# target register map
Vendor: Vango; Series: TARGET; File version: 1.0
CPU: CM0 r0p0, little endian, no MPU, no FPU, 2 interrupt priority bits
Registers are 32-bit, read-write, reset 0x0 unless marked. A register's access mark holds for its fields unless they carry their own. Offsets are from the block's base; [hi:lo] are bit positions; {n}, {i} and the like mark numbered series; 'fields as' and 'values as' point back to an identical list.

## ANA — The Analog controller is used to control the analog function of TARGET.
Base 0x40014200
0x00 REG0 (reset mask 0xFF) — Analog register 0.
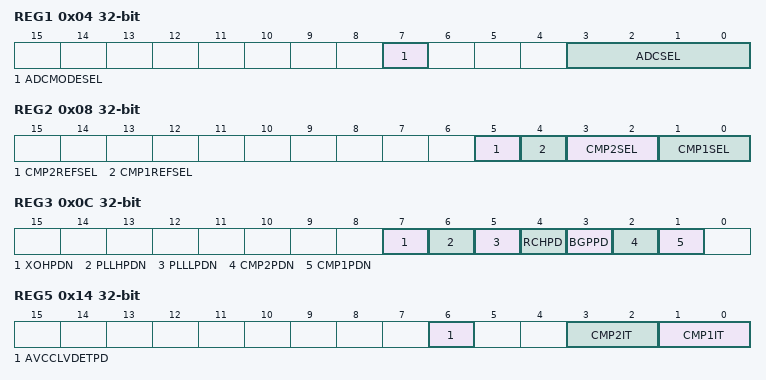
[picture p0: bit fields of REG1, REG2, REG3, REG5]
0x04 REG1 — Analog register 1.
  [7] ADCMODESEL — ADC mode select.
  [3:0] ADCSEL read-olny — ADC channel select.
0x08 REG2 — Analog register 2.
  [5] CMP2REFSEL — REF selection of CMP2.
  [4] CMP1REFSEL — REF selection of CMP1.
  [3:2] CMP2SEL — Signal source selection of comparator 2.
    0=CMP2_P_to_REF; 1=CMP2_N_to_REF; 0b1x=CMP2_P_to_N
  [1:0] CMP1SEL — Signal source selection of comparator 1.
    0=CMP1_P_to_REF; 1=CMP1_N_to_REF; 0b1x=CMP1_P_to_N
0x0C REG3 — Analog register 3.
  [7] XOHPDN — Turn on signal of 6.5536M crystal
  [6] PLLHPDN — PLLH (6.5536MHz input PLL) power up control signal.
  [5] PLLLPDN — PLLL (32768Hz input PLL) power up control signal.
  [4] RCHPD — RCH (6.5536M RC) power down control signal.
  [3] BGPPD — BGP power down control signal.
  [2] CMP2PDN — CMP2 power up control signal.
  [1] CMP1PDN — CMP1 power up control signal.
0x10 REG4 (reset mask 0xFF) — Analog register 4.
0x14 REG5 — Analog register 5.
  [6] AVCCLVDETPD — Power down low voltage detector.
  [3:2] CMP2IT — Bias current selection of CMP2
    0=20nA; 1=100nA; 0b1x=500nA
  [1:0] CMP1IT — Bias current selection of CMP1.
    0=20nA; 1=100nA; 0b1x=500nA
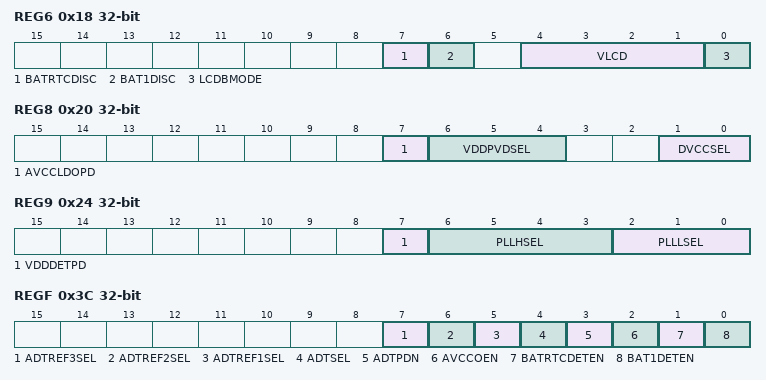
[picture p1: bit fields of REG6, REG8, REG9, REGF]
0x18 REG6 — Analog register 6.
  [7] BATRTCDISC — Discharge the BATRTC battery.
  [6] BAT1DISC — Discharge the BAT1 battery.
  [4:1] VLCD — LCD driving voltage.
  [0] LCDBMODE — LCD BIAS mode selection.
0x1C REG7 — Analog register 7.
  [2] VDCINHYSSEL — VDCIN comparator hysteresis.
0x20 REG8 — Analog register 8.
  [7] AVCCLDOPD — AVCC Power-down control signal.
  [6:4] VDDPVDSEL — Voltage selection of VDD power detector.
    0=4_5V; 1=4_2V; 2=3_9V; 3=3_6V; 4=3_2V; 5=2_9V; 6=2_6V; 7=2_3V
  [1:0] DVCCSEL — DVCC Voltage adjustment.
    0=Add_0_0V; 1=Add_0_1V; 2=Sub_0_1V; 3=Add_0_2V
0x24 REG9 — Analog register 9.
  [7] VDDDETPD — Power down VDD input POWALARM detector.
  [6:3] PLLHSEL — Frequency selection of PLLH.
    0=4x_Input_clock; 1=4_5x_Input_clock; 2=5x_Input_clock; 3=5_5x_Input_clock; 4=6x_Input_clock; 5=6_5x_Input_clock; 6=7x_Input_clock; 7=7_5x_Input_clock; 12=2x_Input_clock; 13=2_5x_Input_clock; 14=3x_Input_clock; 15=3_5x_Input_clock
  [2:0] PLLLSEL — Frequency selection of PLLL
    0=26_2144MHz; 1=13_1072MHz; 2=6_5536MHz; 3=3_2768MHz; 4=1_6384MHz; 5=0_8192MHz; 6=0_4096MHz; 7=0_2048MHz
0x28 REGA — Analog register 10.
  [7] VDCINDETPD — PD VDCIN detector.
0x2C REGB — Analog register 11.
  [4:0] RCLTRIM — Trimming of 32kHz RC. 00000~01111: increased by 4% for each step; 10000~11111: decreased by 4% for each step;
0x30 REGC — Analog register 12.
  [5:0] RCHTRIM — Trimming of 6.5536MHz RC. 000000~011111: increased by 1.25% for each step; 100000~111111: decreased by 1.25% for each step;
0x34 REGD (reset mask 0xFF) — Analog register 13.
0x38 REGE — Analog register 14.
  [7] BKPWREN — BK.power enable.
0x3C REGF — Analog register 15.
  [7] ADTREF3SEL — REF3 of ADT selection.
  [6] ADTREF2SEL — REF2 of ADT selection.
  [5] ADTREF1SEL — REF1 of ADT selection.
  [4] ADTSEL — Signal selection for ADT.
  [3] ADTPDN — Power up Tiny ADC.
  [2] AVCCOEN — Power on AVCC_OUT pin.
  [1] BATRTCDETEN — Enabe connection from BATRTC to Comparator2‘s positive input.
  [0] BAT1DETEN — Enabe connection from BAT1 to Comparator1‘s positive input.
0x40 REG10 (reset mask 0x8F) — Analog register 16.
0x44 REG11 (reset mask 0xFF) — Analog register 17.
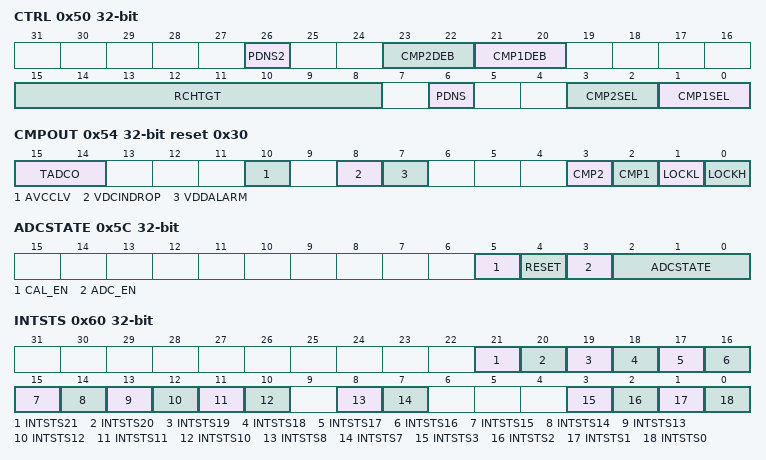
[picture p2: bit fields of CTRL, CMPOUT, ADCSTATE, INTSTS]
0x50 CTRL — Analog control register.
  [26] PDNS2 — This register is used to set the deep sleep behavior when PWRALRAM is 0. (Still need to consider the PDNS setting).
  [23:22] CMP2DEB — Comparator 2 de-bounce control register.
    0=No_debounce; 1=2_32KHz_debounce; 2=3_32KHz_debounce; 3=4_32KHz_debounce
  [21:20] CMP1DEB — Comparator 1 de-bounce control register.
    values as CMP2DEB
  [15:8] RCHTGT — RCH auto calibration target register.
  [6] PDNS — This register is used to set the deep sleep behavior when PWRDROP is 0(Still need to consider the PDNS setting).
  [3:2] CMP2SEL — This register is used to control the interrupt and wake-up signal generation of CMP2.
    0=Off; 1=Rising; 2=Falling; 3=Both
  [1:0] CMP1SEL — This register is used to control the interrupt and wake-up signal generation of CMP1.
    0=Off; 1=Rising; 2=Falling; 3=Both
0x54 CMPOUT ro reset 0x30 — Comparator result register.
  [15:14] TADCO — Tiny ADC output.
  [10] AVCCLV — AVCCLV low power status.
  [8] VDCINDROP — VDCIN drop status.
  [7] VDDALARM — This bit shows the output of VDDALARM.
  [3] CMP2 — This bit shows the output of comparator 2.
  [2] CMP1 — This bit shows the output of comparator 1.
  [1] LOCKL — PLLL lock status.
  [0] LOCKH — PLLH lock status.
0x5C ADCSTATE ro
  [5] CAL_EN — This bit shows the status of CAL_EN in the ADC interface.
  [4] RESET — This bit shows the status of RESET in the ADC interface.
  [3] ADC_EN — This bit shows the status of ADC_EN in the ADC interface.
  [2:0] ADCSTATE — These bits show the state of ADC controller state machine.
    0=Idle; 2=Auto_Trigger; 4=Manually_Trigger
0x60 INTSTS — Analog interrupt status register.
  [21] INTSTS21 write-1-clears — ADC data over UPPER_THD3.
  [20] INTSTS20 write-1-clears — ADC data over LOWER_THD3.
  [19] INTSTS19 write-1-clears — ADC data over UPPER_THD2.
  [18] INTSTS18 write-1-clears — ADC data below LOWER_THD2.
  [17] INTSTS17 write-1-clears — ADC data over UPPER_THD1.
  [16] INTSTS16 write-1-clears — ADC data below LOWER_THD1.
  [15] INTSTS15 write-1-clears — ADC data over UPPER_THD0.
  [14] INTSTS14 write-1-clears — ADC data below LOWER_THD0.
  [13] INTSTS13 write-1-clears — TADC change over-threshold interrupt.
  [12] INTSTS12 write-1-clears — ANA_REGx error flag.
  [11] INTSTS11 write-1-clears — Interrupt flag of sleep mode entry under PWRDROP is 0.
  [10] INTSTS10 write-1-clears — Interrupt flag of POWLV, this interrupt will be generated when POWLV rising or falling.
  [8] INTSTS8 write-1-clears — Interrupt flag of PWRDROP.
  [7] INTSTS7 write-1-clears — Interrupt flag of POWALARM.
  [3] INTSTS3 write-1-clears — Interrupt flag of CMP2.
  [2] INTSTS2 write-1-clears — Interrupt flag of CMP1.
  [1] INTSTS1 write-1-clears — Interrupt flag of auto ADC conversion done.
  [0] INTSTS0 write-1-clears — Interrupt flag of manual ADC conversion done.
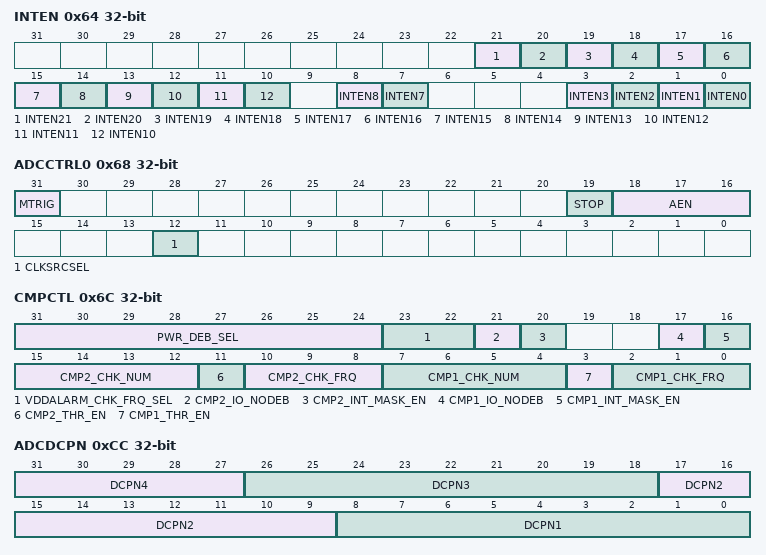
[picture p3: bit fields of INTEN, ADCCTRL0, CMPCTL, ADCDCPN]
0x64 INTEN — Analog interrupt enable register.
  [21] INTEN21 — Interrupt and wake-up enable control of ADC CH3 data over threshold.
  [20] INTEN20 — Interrupt and wake-up enable control of ADC CH3 data below threshold.
  [19] INTEN19 — Interrupt and wake-up enable control of ADC CH2 data over threshold.
  [18] INTEN18 — Interrupt and wake-up enable control of ADC CH2 data below threshold.
  [17] INTEN17 — Interrupt and wake-up enable control of ADC CH1 data over threshold.
  [16] INTEN16 — Interrupt and wake-up enable control of ADC CH1 data below threshold.
  [15] INTEN15 — Interrupt and wake-up enable control of ADC CH0 data over threshold.
  [14] INTEN14 — Interrupt and wake-up enable control of ADC CH0 data below threshold.
  [13] INTEN13 — Interrupt and wake-up enable control of TADC change over threshold.
  [12] INTEN12 — Interrupt and wake-up enable control of ANA_REGx error.
  [11] INTEN11 — Interrupt and wake-up enable control of sleep mode entry, when VDCINDROP is 0.
  [10] INTEN10 — Interrupt and wake-up enable control of POWLV.
  [8] INTEN8 — Interrupt and wake-up enable control of PWRDROP.
  [7] INTEN7 — Interrupt and wake-up enable control of POWALARM.
  [3] INTEN3 — Interrupt and wake-up enable control of CMP2.
  [2] INTEN2 — Interrupt and wake-up enable control of CMP1.
  [1] INTEN1 — Interrupt enable control of auto ADC conversion done.
  [0] INTEN0 — Interrupt enable control of manual ADC conversion done.
0x68 ADCCTRL0 — ADC control register.
  [31] MTRIG — Manual ADC trigger.
  [19] STOP — Force stop current ADC conversion process.
  [18:16] AEN — Auto ADC conversion enable control register.
    0=Off; 1=RTC_ITV_and_RTC_SITV (Auto ADC will be triggered by RTC_INTSTS[0] that is determined by RTC_ITV and RTC_SITV.); 2=RTC_WKUSEC; 3=RTC_ALARM; {v}=Timer{v-4}_overflow (v=4..7)
  [12] CLKSRCSEL — ADC clock source selection.
    0=RCH; 1=PLLL
0x6C CMPCTL — CMP1/CMP2 control register.
  [31:24] PWR_DEB_SEL — VDDALARM, VDCIN and AVCCDET de-bounce control register.
  [23:22] VDDALARM_CHK_FRQ_SEL — VDDALARM check data frequency
    0=No_check; 1=Always_check_by_32KHz; 2=Checked_every_7_8125ms
  [21] CMP2_IO_NODEB — The CMP2 output of IO port de-bounce control.
  [20] CMP2_INT_MASK_EN — When CMP2_CNT exceeds the CMP2_THR and CMP2_THE_EN = 1, only one interrupt is generated.
  [17] CMP1_IO_NODEB — The CMP1 output of IO port de-bounce control.
  [16] CMP1_INT_MASK_EN — When CMP1_CNT exceeds the CMP1_THR and CMP1_THE_EN = 1, only one interrupt is generated.
  [15:12] CMP2_CHK_NUM — CMP2 check data number of time. 0~15: 1 time ~ 16 times
  [11] CMP2_THR_EN — CMP2 data over this setting would trigger the interrupt enable
  [10:8] CMP2_CHK_FRQ — CMP2 check data frequency.
    0=Every_clock; 1=Every_7_8125ms; 2=Every_125ms; 3=Every_250ms; 4=Every_500ms; 5=Every_clock; 0b11x=Every_clock
  [7:4] CMP1_CHK_NUM — CMP1 check data number of time. 0~15: 1 time ~ 16 times
  [3] CMP1_THR_EN — CMP1 data over this setting would trigger the interrupt enable
  [2:0] CMP1_CHK_FRQ — CMP1 check data frequence.
    values as CMP2_CHK_FRQ
{0x70+4i} ADCDATA[{i}] (i=0..15) ro reset not defined — ADC channel x data register.
  [15:0] ADCDATA — The result of ADC conversion will be stored in these registers.x=0~15.
{0xAC+4i} CMPCNT{i} (i=1..2) — Comparator x counter.
  [31:0] CNT — This register store the happen times of comparator x according to the setting in COMPx_SEL.
0xB8 MISC — Analog MISC control register.
  [5:4] TADCTH — TADC threshold setting.
0xC0 ADCDOS ro reset not defined — ANA_ADCDOS.
  [8:0] DOS — ADC DOS.
0xCC ADCDCPN ro reset not defined — ANA_ADCDCPN.
  [31:27] DCPN4 — ADC DCPN4.
  [26:18] DCPN3 — ADC DCPN3.
  [17:9] DCPN2 — ADC DCPN2.
  [8:0] DCPN1 — ADC DCPN1.
0xD8 ADCDCNM0 ro reset not defined — ANA_ADCDCNM0.
  [8:0] NM0 — ADC NM0.
0xE0 ADCDATADMA ro reset not defined — ANA_ADCDATADMA.
  [15:0] ADCDATA_DMA — ADC data source for DMA.
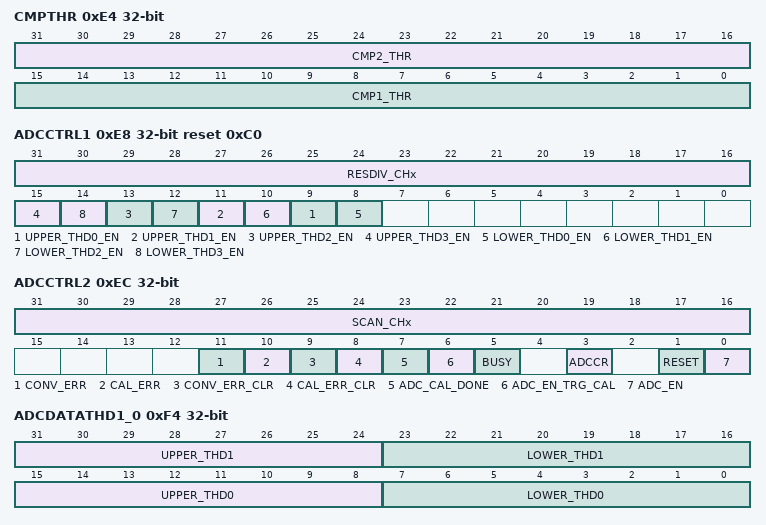
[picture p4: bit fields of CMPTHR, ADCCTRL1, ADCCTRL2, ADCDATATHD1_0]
0xE4 CMPTHR — CMP1/CMP2 threshold register.
  [31:16] CMP2_THR — CMP2 data over this setting would trigger the interrupt.
  [15:0] CMP1_THR — CMP1 data over this setting would trigger the interrupt.
0xE8 ADCCTRL1 reset 0xC0 — ANA_ADCCTRL1.
  [31:16] RESDIV_CHx — BITy Control CHx RESDIV enable. y=31~16, x=15~0.
  [2n+9] UPPER_THD{n}_EN (n=0..3) — UPPER_THD{n} Enable
  [2n+8] LOWER_THD{n}_EN (n=0..3) — LOWER_THD{n} Enable
0xEC ADCCTRL2 — ANA_ADCCTRL2.
  [31:16] SCAN_CHx — BITy Control CHx auto-scan enable. y=31~16, x=15~0.
  [11] CONV_ERR — CONV_ERR in ADC interface
  [10] CAL_ERR — CAL_ERR in ADC interface
  [9] CONV_ERR_CLR — CONV_ERR_CLR in ADC interface
  [8] CAL_ERR_CLR — CAL_ERR_CLR in ADC interface
  [7] ADC_CAL_DONE — Indicate automatic CAL_EN flow done
  [6] ADC_EN_TRG_CAL — 1: Writing 1 to ADC_EN will trigger automatic CAL_EN flow.
  [5] BUSY — BUSY in ADC interface
  [3] ADCCR — ADCCR in ADC interface
  [1] RESET — RESET in ADC interface, driven by CPU
  [0] ADC_EN — ADC Enabe.
0xF4 ADCDATATHD1_0 — ANA_ADCDATATHD1_0.
  [31:24] UPPER_THD1 — ADC data over this setting would trigger the interrupt or status update FF: Disable
  [23:16] LOWER_THD1 — ADC data below this setting would trigger the interrupt or status update 00: Disable
  [15:8] UPPER_THD0 — ADC data over this setting would trigger the interrupt or status update FF: Disable
  [7:0] LOWER_THD0 — ADC data below this setting would trigger the interrupt or status update 00: Disable
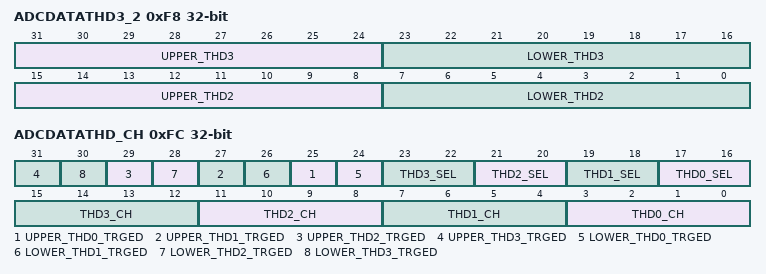
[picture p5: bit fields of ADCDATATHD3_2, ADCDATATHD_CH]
0xF8 ADCDATATHD3_2 — ANA_ADCDATATHD3_2.
  [31:24] UPPER_THD3 — ADC data over this setting would trigger the interrupt or status update FF: Disable
  [23:16] LOWER_THD3 — ADC data below this setting would trigger the interrupt or status update 00: Disable
  [15:8] UPPER_THD2 — ADC data over this setting would trigger the interrupt or status update FF: Disable
  [7:0] LOWER_THD2 — ADC data below this setting would trigger the interrupt or status update 00: Disable
0xFC ADCDATATHD_CH — ANA_ADCDATATHD_CH.
  [2n+25] UPPER_THD{n}_TRGED (n=0..3) — This register is to reflect UPPER_THD{n} triggered status.
  [2n+24] LOWER_THD{n}_TRGED (n=0..3) — This register is to reflect LOWER_THD{n} triggered status.
  [2n+17:2n+16] THD{n}_SEL (n=0..3) — This register is used to control the interrupt signal generation of UPPER_THD{n} and LOWER_THD{n}.
    0=High_Level; 1=Rising_edge; 2=Falling_edge; 3=Both_of_edge
  [4n+3:4n] THD{n}_CH (n=0..3) — The channel number(0~15) to enable LOWER_THD{n} and UPPER_THD{n}.
